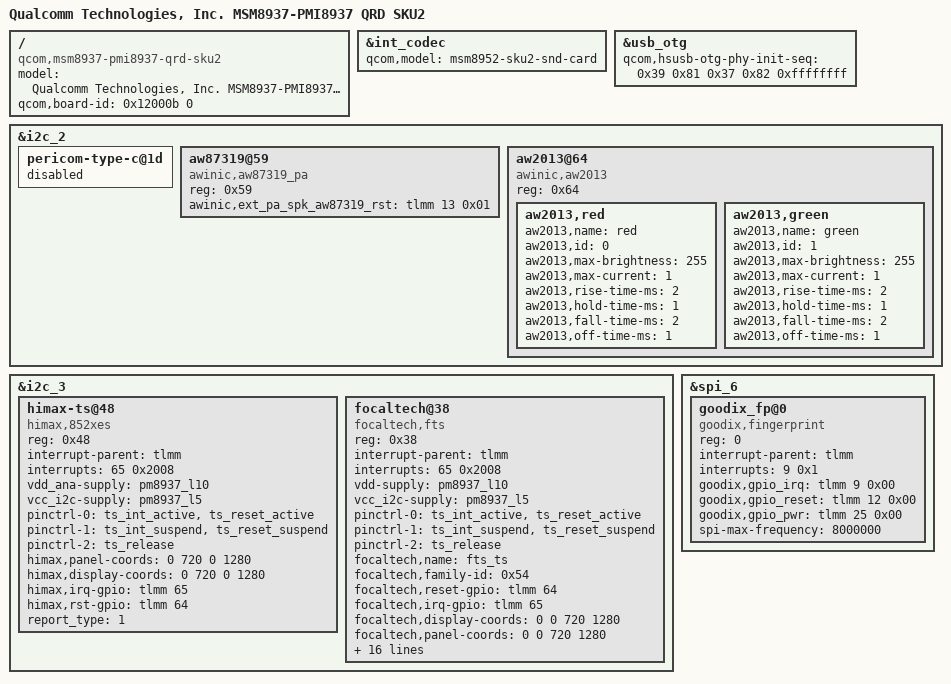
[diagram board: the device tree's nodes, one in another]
/*
 * Copyright (c) 2015-2016, The Linux Foundation. All rights reserved.
 *
 * This program is free software; you can redistribute it and/or modify
 * it under the terms of the GNU General Public License version 2 and
 * only version 2 as published by the Free Software Foundation.
 *
 * This program is distributed in the hope that it will be useful,
 * but WITHOUT ANY WARRANTY; without even the implied warranty of
 * MERCHANTABILITY or FITNESS FOR A PARTICULAR PURPOSE.  See the
 * GNU General Public License for more details.
 */

/dts-v1/;

#include "msm8937.dtsi"
#include "msm8937-pmi8937-qrd-sku2.dtsi"

/ {
	model = "Qualcomm Technologies, Inc. MSM8937-PMI8937 QRD SKU2";
	compatible = "qcom,msm8937-pmi8937-qrd-sku2",
		   "qcom,msm8937-qrd", "qcom,msm8937", "qcom,qrd";
	qcom,board-id= <0x12000b 0>;
};

&int_codec {
	qcom,model = "msm8952-sku2-snd-card";
};

&usb_otg {
	qcom,hsusb-otg-phy-init-seq =
		<0x39 0x81 0x37 0x82 0xffffffff>;
};

&i2c_2 {
	pericom-type-c@1d {
		status="disabled";
	};

        /* for AW87319 sound Speaker PA */
        aw87319@59{
                compatible = "awinic,aw87319_pa";
                reg = <0x59>;
                awinic,ext_pa_spk_aw87319_rst = <&tlmm 13 0x01>;
        };


aw2013@64 {/* add for breath led. */
		compatible = "awinic,aw2013";
		reg = <0x64>;
		//vdd-supply = <&pm8937_l17>;
		//vcc-supply = <&pm8937_l5>;

		aw2013,red {
			aw2013,name = "red";
			aw2013,id = <0>;
			aw2013,max-brightness = <255>;
			aw2013,max-current = <1>;
			aw2013,rise-time-ms = <2>;
			aw2013,hold-time-ms = <1>;
			aw2013,fall-time-ms = <2>;
			aw2013,off-time-ms = <1>;
		};

		aw2013,green {
			aw2013,name = "green";
			aw2013,id = <1>;
			aw2013,max-brightness = <255>;
			aw2013,max-current = <1>;
			aw2013,rise-time-ms = <2>;
			aw2013,hold-time-ms = <1>;
			aw2013,fall-time-ms = <2>;
			aw2013,off-time-ms = <1>;
		};
};
};


&i2c_3 { /* BLSP1 QUP3 */
		status = "ok";
		himax-ts@48 {
			compatible = "himax,852xes";
			reg = <0x48>;
			interrupt-parent = <&tlmm>;
			interrupts = <65 0x2008>;
			vdd_ana-supply = <&pm8937_l10>;
			vcc_i2c-supply = <&pm8937_l5>;
			/* pinctrl used for tp add 04.05.2017 */
			pinctrl-names = "pmx_ts_active","pmx_ts_suspend",
				"pmx_ts_release";
			pinctrl-0 = <&ts_int_active &ts_reset_active>;
			pinctrl-1 = <&ts_int_suspend &ts_reset_suspend>;
			pinctrl-2 = <&ts_release>;
			himax,panel-coords = <0 720 0 1280>;/*480 800 */
			himax,display-coords = <0 720 0 1280>;/*480 800 */
			himax,irq-gpio = <&tlmm 65 0x00>;
			himax,rst-gpio = <&tlmm 64 0x00>;
			report_type = <1>;
		};

		focaltech@38{
			compatible = "focaltech,fts";
			reg = <0x38>;
			interrupt-parent = <&tlmm>;
			interrupts = <65 0x2008>;
			vdd-supply = <&pm8937_l10>;
			vcc_i2c-supply = <&pm8937_l5>;
			/* pins used by touchscreen */
			pinctrl-names = "pmx_ts_active","pmx_ts_suspend",
				"pmx_ts_release";
			pinctrl-0 = <&ts_int_active &ts_reset_active>;
			pinctrl-1 = <&ts_int_suspend &ts_reset_suspend>;
			pinctrl-2 = <&ts_release>;
			focaltech,name = "fts_ts";
			focaltech,family-id = <0x54>;
			focaltech,reset-gpio = <&tlmm 64 0x00>;
			focaltech,irq-gpio = <&tlmm 65 0x2008>;
			focaltech,display-coords = <0 0 720 1280>;
			focaltech,panel-coords = <0 0 720 1280>;
			/*ftech,button-map= <139 102 158>;*/
			focaltech,virtual-key1 = <1344 600 2000>;/*menu*/
			/*focaltech,virtual-key2 = <120 1350 2000>;home*/
			focaltech,virtual-key3 = <1344 160 2000>;/*back*/
			focaltech,no-force-update;
			focaltech,i2c-pull-up;
			focaltech,group-id = <1>;
			focaltech,hard-reset-delay-ms = <20>;
			focaltech,soft-reset-delay-ms = <300>;
			focaltech,num-max-touches = <10>;
			focaltech,fw-delay-aa-ms = <30>;
			focaltech,fw-delay-55-ms = <30>;
			focaltech,fw-upgrade-id1 = <0x79>;
			focaltech,fw-upgrade-id2 = <0x18>;
			focaltech,fw-delay-readid-ms = <10>;
			focaltech,fw-delay-era-flsh-ms = <2000>;
			focaltech,fw-auto-cal;
			focaltech,ignore-id-check;
		};
};

//goodix fingerprint
&spi_6 { /* BLSP1 QUP3 */
               status = "ok";
               goodix_fp@0 {
                       status = "ok";
                       compatible = "goodix,fingerprint";
                       reg = <0>;
                       interrupt-parent = <&tlmm>;
                       interrupts = <9 0x1>;
                       goodix,gpio_irq = <&tlmm 9 0x00>;
                       goodix,gpio_reset = <&tlmm 12 0x00>;
                       goodix,gpio_pwr = <&tlmm 25 0x00>;
                       spi-max-frequency = <8000000>;
               };
       };
